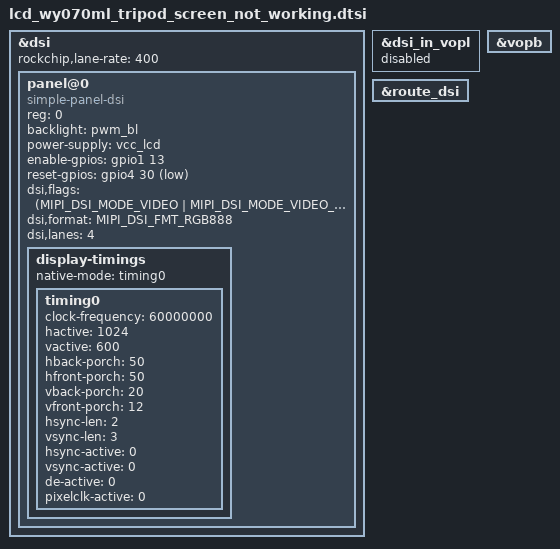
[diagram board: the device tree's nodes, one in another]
&dsi {
	status = "okay";
	rockchip,lane-rate = <400>;
	panel@0 {
		compatible ="simple-panel-dsi";
		reg = <0>;
		backlight = <&pwm_bl>;
		power-supply = <&vcc_lcd>;
		enable-gpios = <&gpio1 13 GPIO_ACTIVE_HIGH>;
		reset-gpios = <&gpio4 30 GPIO_ACTIVE_LOW>;
		dsi,flags = <(MIPI_DSI_MODE_VIDEO | MIPI_DSI_MODE_VIDEO_BURST |
				MIPI_DSI_MODE_VIDEO_SYNC_PULSE)>;
		dsi,format = <MIPI_DSI_FMT_RGB888>;
		dsi,lanes = <4>;
		status = "okay";

		display-timings {
			native-mode = <&timing0>;
			timing0: timing0 {
				clock-frequency = <60000000>;
				hactive = <1024>;
				vactive = <600>;
				hback-porch = <50>;
				hfront-porch = <50>;
				vback-porch = <20>;
				vfront-porch = <12>;
				hsync-len = <2>;
				vsync-len = <3>;
				hsync-active = <0>;
				vsync-active = <0>;
				de-active = <0>;
				pixelclk-active = <0>;
			};
		};
	};
};

&dsi_in_vopl {
	status = "disabled";
};

&route_dsi {
	status = "okay";
};

&vopb {
		status = "okay";
};
